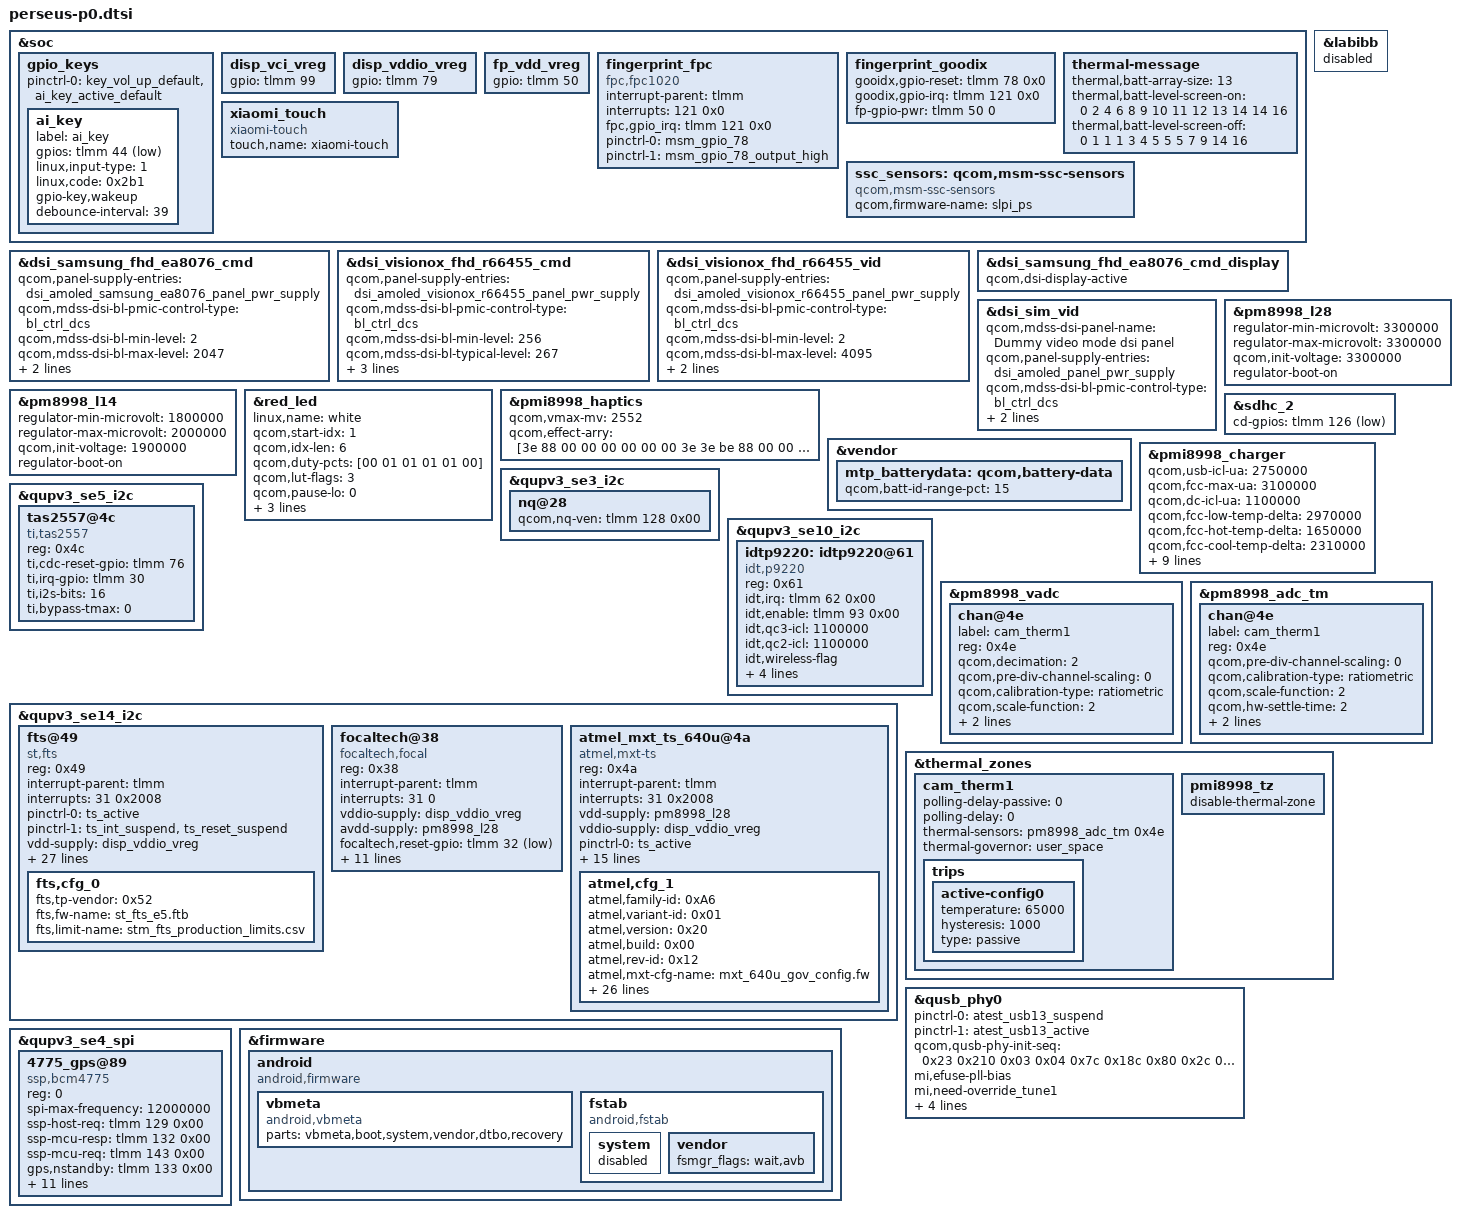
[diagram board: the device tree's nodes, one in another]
/* Copyright (c) 2016-2017, The Linux Foundation. All rights reserved.
 * Copyright (C) 2019 XiaoMi, Inc.
 *
 * This program is free software; you can redistribute it and/or modify
 * it under the terms of the GNU General Public License version 2 and
 * only version 2 as published by the Free Software Foundation.
 *
 * This program is distributed in the hope that it will be useful,
 * but WITHOUT ANY WARRANTY; without even the implied warranty of
 * MERCHANTABILITY or FITNESS FOR A PARTICULAR PURPOSE.  See the
 * GNU General Public License for more details.
 */

#include "../xiaomi-sdm845-common.dtsi"
#include "perseus-p0-camera-sensor-mtp.dtsi"

&soc {
	gpio_keys {
		pinctrl-0 = <&key_vol_up_default &ai_key_active_default>;
		ai_key {
			label = "ai_key";
			gpios = <&tlmm 44 GPIO_ACTIVE_LOW>;
			linux,input-type = <1>;
			linux,code = <0x2b1>;
			gpio-key,wakeup;
			debounce-interval = <39>;
		};
	};

	disp_vci_vreg {
		gpio = <&tlmm 99 0>;
	};

	disp_vddio_vreg {
		gpio = <&tlmm 79 0>;
	 };

	fp_vdd_vreg {
		gpio = <&tlmm 50 0>;
	};

	fingerprint_fpc {
		status = "ok";
		compatible = "fpc,fpc1020";
		interrupt-parent = <&tlmm>;
		interrupts = <121 0x0>;
		fpc,gpio_irq    = <&tlmm 121 0x0>;
		/* fpc,enable-on-boot; */
		/* fpc,enable-wakeup;  */

		pinctrl-names = "fpc1020_reset_reset",
			"fpc1020_reset_active";

		pinctrl-0 = <&msm_gpio_78>;
		pinctrl-1 = <&msm_gpio_78_output_high>;
	};

	fingerprint_goodix {
		gooidx,gpio-reset = <&tlmm 78 0x0>;
		goodix,gpio-irq = <&tlmm 121 0x0>;
		fp-gpio-pwr = <&tlmm 50 0>;
	};

	thermal-message {
		thermal,batt-array-size = "13";
		thermal,batt-level-screen-on = "0 2 4 6 8 9 10 11 12 13 14 14 16";
		thermal,batt-level-screen-off = "0 1 1 1 3 4 5 5 5 7 9 14 16";
	};

	xiaomi_touch {
		compatible = "xiaomi-touch";
		status = "ok";
		touch,name = "xiaomi-touch";
	};

};

&labibb {
	status = "disabled";
};

&dsi_samsung_fhd_ea8076_cmd {
	qcom,panel-supply-entries = <&dsi_amoled_samsung_ea8076_panel_pwr_supply>;
	qcom,mdss-dsi-bl-pmic-control-type = "bl_ctrl_dcs";
	qcom,mdss-dsi-bl-min-level = <2>;
	qcom,mdss-dsi-bl-max-level = <2047>;
	qcom,platform-reset-gpio = <&tlmm 6 0>;
	qcom,platform-te-gpio = <&tlmm 10 0>;
};

&dsi_visionox_fhd_r66455_cmd {
	qcom,panel-supply-entries = <&dsi_amoled_visionox_r66455_panel_pwr_supply>;
	qcom,mdss-dsi-bl-pmic-control-type = "bl_ctrl_dcs";
	qcom,mdss-dsi-bl-min-level = <256>;
	qcom,mdss-dsi-bl-typical-level = <267>;
	qcom,mdss-dsi-bl-max-level = <4095>;
	qcom,platform-reset-gpio = <&tlmm 6 0>;
	qcom,platform-te-gpio = <&tlmm 10 0>;
};

&dsi_visionox_fhd_r66455_vid {
	qcom,panel-supply-entries = <&dsi_amoled_visionox_r66455_panel_pwr_supply>;
	qcom,mdss-dsi-bl-pmic-control-type = "bl_ctrl_dcs";
	qcom,mdss-dsi-bl-min-level = <2>;
	qcom,mdss-dsi-bl-max-level = <4095>;
	qcom,platform-reset-gpio = <&tlmm 6 0>;
	qcom,platform-te-gpio = <&tlmm 10 0>;
};

&dsi_samsung_fhd_ea8076_cmd_display {
	qcom,dsi-display-active;
};

&dsi_sim_vid {
	qcom,mdss-dsi-panel-name = "Dummy video mode dsi panel";
	qcom,panel-supply-entries = <&dsi_amoled_panel_pwr_supply>;
	qcom,mdss-dsi-bl-pmic-control-type = "bl_ctrl_dcs";
	qcom,platform-reset-gpio = <&tlmm 6 0>;
	qcom,mdss-dsi-te-pin-select = <0>;
};

&pm8998_l28{
	regulator-min-microvolt = <3300000>;
	regulator-max-microvolt = <3300000>;
	qcom,init-voltage = <3300000>;
	regulator-boot-on;
};

&pm8998_l14 {
	regulator-min-microvolt = <1800000>;
	regulator-max-microvolt = <2000000>;
	qcom,init-voltage = <1900000>;
	regulator-boot-on;
};

&red_led {
	linux,name = "white";
	qcom,start-idx = <1>;
	qcom,idx-len = <6>;
	qcom,duty-pcts = [00 01 01 01 01 00];
	qcom,lut-flags = <3>;
	qcom,pause-lo = <0>;
	qcom,pause-hi = <0>;
	qcom,ramp-step-ms = <400>;
	qcom,use-blink;
	status = "okay";
};

&pmi8998_haptics {
	qcom,vmax-mv = <2552>;
	qcom,effect-arry = [3e 88 00 00 00 00 00 00
	3e 3e be 88 00 00 00 00
	3e 3e 3e be a0 00 00 00];
};

&sdhc_2 {
	cd-gpios = <&tlmm 126 GPIO_ACTIVE_LOW>;
};

&vendor{
	mtp_batterydata: qcom,battery-data {
		qcom,batt-id-range-pct = <15>;
		#include "../battery/batterydata-e5-sun-3200mAh.dtsi"
		#include "../battery/batterydata-e5-cos-3200mAh.dtsi"
		#include "../battery/batterydata-itech-3020mAh.dtsi"
	};
};

&pmi8998_charger {
	qcom,usb-icl-ua = <2750000>;
	qcom,fcc-max-ua = <3100000>;
	qcom,dc-icl-ua = <1100000>;
	qcom,fcc-low-temp-delta = <2970000>;
	qcom,fcc-hot-temp-delta = <1650000>;
	qcom,fcc-cool-temp-delta = <2310000>;
	qcom,use-ext-boost;
	qcom,wireless-support;
	qcom,thermal-mitigation-dc
				= <1100000 700000 525000 450000 325000>;
	qcom,thermal-mitigation-qc3
				= <2800000 2725000 2575000 2425000 2275000 2125000 2000000
				   1800000 1650000 1500000 1360000 1200000 1060000 900000
				   752500 525000>;

	io-channels = <&pmi8998_rradc 8>,
		<&pmi8998_rradc 10>,
		<&pmi8998_rradc 3>,
		<&pmi8998_rradc 4>,
		<&pmi8998_rradc 5>;
	io-channel-names = "charger_temp",
		"charger_temp_max",
		"usbin_i",
		"usbin_v",
		"dcin_i";
};

&qupv3_se3_i2c {
	status = "ok";
	nq@28 {
		qcom,nq-ven = <&tlmm 128 0x00>;
	};
};

&qupv3_se5_i2c {
	status = "ok";
	/*smart PA*/
	tas2557@4c{
		compatible = "ti,tas2557";
		reg = <0x4c>;
		ti,cdc-reset-gpio = <&tlmm 76 0>;
		ti,irq-gpio = <&tlmm 30 0>;
		ti,i2s-bits = <16>;
		ti,bypass-tmax = <0>;
	};
};

&qupv3_se10_i2c {
	status = "ok";
	idtp9220: idtp9220@61 {
		compatible = "idt,p9220";
		reg = <0x61>;
		idt,irq = <&tlmm 62 0x00>;
		idt,enable = <&tlmm 93 0x00>;
		idt,qc3-icl = <1100000>;
		idt,qc2-icl = <1100000>;
		idt,wireless-flag;
		interrupt-parent = <&tlmm>;
		interrupts = <62 0>;
		interrupt-names = "idt_irq";
		pinctrl-names = "idt_active", "idt_suspend";
		pinctrl-0 = <&idt_int_active &idt_enable_active>;
		pinctrl-1 = <&idt_int_suspend &idt_enable_suspend>;
	};
};

&qupv3_se14_i2c {
	status = "ok";
	fts@49 {
		compatible = "st,fts";
		reg = <0x49>;
		interrupt-parent = <&tlmm>;
		interrupts = <31 0x2008>;
		pinctrl-names = "pmx_ts_active", "pmx_ts_suspend";
		pinctrl-0 = <&ts_active>;
		pinctrl-1 = <&ts_int_suspend &ts_reset_suspend>;
		vdd-supply = <&disp_vddio_vreg>;
		avdd-supply = <&pm8998_l28>;
		fts,pwr-reg-name = "avdd";
		fts,bus-reg-name = "vdd";
		fts,irq-gpio = <&tlmm 31 0x2008>;
		fts,irq-gpio-name = "fts_irq";
		fts,reset-gpio-enable;
		fts,reset-gpio = <&tlmm 32 0x00>;
		fts,x-max = <1079>;
		fts,y-max = <2339>;
		fts,reset-gpio-name = "fts_rst";
		fts,irq-flags = <0x2008>; /* IRQF_ONESHOT | IRQF_TRIGGER_LOW */
		fts,key-num = <2>;
		fts,key-codes = <158 139>;
		fts,config-array-size = <1>;
		fts,check-display-name;
		fts,default-fw-name = "st_fts_e5.ftb";
		fts,touch-up-threshold-min = <20>;
		fts,touch-up-threshold-max = <170>;
		fts,touch-up-threshold-def = <20>;
		fts,touch-tolerance-min = <5>;
		fts,touch-tolerance-max = <35>;
		fts,touch-tolerance-def = <5>;
		fts,edgefilter-leftrigt-def = <40>;
		fts,edgefilter-topbottom-def = <40>;
		fts,edgefilter-area-step1 = <100>;
		fts,edgefilter-area-step2 = <150>;
		fts,edgefilter-area-step3 = <250>;
		fts,cfg_0 {
			fts,tp-vendor = <0x52>;
			fts,fw-name = "st_fts_e5.ftb";
			fts,limit-name = "stm_fts_production_limits.csv";
		};
	};
	focaltech@38 {
		compatible = "focaltech,focal";
		reg = <0x38>;
		interrupt-parent = <&tlmm>;
		interrupts = <31 0>;
		vddio-supply = <&disp_vddio_vreg>;
		avdd-supply = <&pm8998_l28>;

		focaltech,reset-gpio = <&tlmm 32 0x01>;
		focaltech,irq-gpio = <&tlmm 31 0x02>;
		focaltech,max-touch-number = <10>;
		focaltech,display-coords = <0 0 1080 2340>;
		focaltech,project-name = "e5";
		focaltech,lockdown-info-addr = <0x1FFD0>;
		focaltech,reset-when-resume;
		focaltech,open-min = <3000>;
		focaltech,timeout-read-reg = <2000>;
		focaltech,check-display-name;
		pinctrl-names = "pmx_ts_active", "pmx_ts_suspend";
		pinctrl-0 = <&ts_active>;
		pinctrl-1 = <&ts_int_suspend &ts_reset_suspend>;
		/* focaltech,have-key; */
	};
	atmel_mxt_ts_640u@4a {
		compatible = "atmel,mxt-ts";
		reg = <0x4a>;
		interrupt-parent = <&tlmm>;
		interrupts = <31 0x2008>;
		vdd-supply = <&pm8998_l28>;
		vddio-supply = <&disp_vddio_vreg>;
		/* pins used by touchscreen */
		pinctrl-names = "pmx_ts_active","pmx_ts_suspend";
		pinctrl-0 = <&ts_active>;
		pinctrl-1 = <&ts_int_suspend &ts_reset_suspend>;
		atmel,reset-gpio = <&tlmm 32 0x00>;
		atmel,reset-low-prepower;
		atmel,irq-gpio = <&tlmm 31 0x2008>;
		atmel,mxt-fw-name = "mXT640U2000.fw";
		atmel,config-array-size = <1>;
		atmel,default-config = <0>;
		atmel,default-panel-id = <0x51>;
		atmel,irqflags = <0x2008>;
		atmel,gpio-mask = <0xC>;
		atmel,esd-reset;
		atmel,no-keys;
		atmel,use-ta-gpio;
		atmel,raw-min = <3000>;
		atmel,raw-max = <7000>;
		atmel,cfg_1 {
			atmel,family-id = <0xA6>;
			atmel,variant-id = <0x01>;
			atmel,version = <0x20>;
			atmel,build = <0x00>;
			atmel,rev-id = <0x12>;
			atmel,mxt-cfg-name = "mxt_640u_gov_config.fw";
			atmel,vendor-id = <0x0C>;
			atmel,panel-id = <0x51>; /* gov id = 0x51 */
			atmel,key-codes = <158 139 102>;
			atmel,selfintthr-stylus = <0>;
			atmel,t71-tchthr-pos = <22>;
			atmel,self-chgtime-min = <0>;
			atmel,self-chgtime-max = <0>;
			atmel,mult-intthr-sensitive = <0x08>;
			atmel,mult-intthr-not-sensitive = <17>;
			atmel,atchthr-sensitive = <6>;
			atmel,mult-tchthr-sensitive = <0x14>;
			atmel,mult-tchthr-not-sensitive = <0>;
			atmel,wake-up-self-adcx = <16>;
			atmel,atchratio = <0>;
			atmel,xycfg = <0x08>;
			atmel,xsize = <0x1e>;
			atmel,xrange-lsb = <0x37>;
			atmel,xrange-msb = <0x04>;
			atmel,tchhyst = <0x0a>;
			atmel,intthrhyst = <0x03>;
			atmel,xtchthr = <0x23>;
			atmel,xtchhyst = <0x0f>;
			atmel,intthrx = <0x08>;
			atmel,ytchthr = <0x23>;
			atmel,ytchhyst = <0x0f>;
			atmel,intthry = <0x08>;
		};
	};
};

&pm8998_vadc {
	chan@4e {
		label = "cam_therm1";
		reg = <0x4e>;
		qcom,decimation = <2>;
		qcom,pre-div-channel-scaling = <0>;
		qcom,calibration-type = "ratiometric";
		qcom,scale-function = <2>;
		qcom,hw-settle-time = <2>;
		qcom,fast-avg-setup = <0>;
	};
};

&pm8998_adc_tm {
	chan@4e {
		label = "cam_therm1";
		reg = <0x4e>;
		qcom,pre-div-channel-scaling = <0>;
		qcom,calibration-type = "ratiometric";
		qcom,scale-function = <2>;
		qcom,hw-settle-time = <2>;
		qcom,btm-channel-number = <0x70>;
		qcom,thermal-node;
	};
};

&thermal_zones {
	cam_therm1 {
		polling-delay-passive = <0>;
		polling-delay = <0>;
		thermal-sensors = <&pm8998_adc_tm 0x4e>;
		thermal-governor = "user_space";

		trips {
			active-config0 {
					temperature = <65000>;
					hysteresis = <1000>;
					type = "passive";
			};
		};
	};

	pmi8998_tz {
		disable-thermal-zone;
	};
};

&qusb_phy0 {
	pinctrl-names = "atest_usb13_suspend","atest_usb13_active";
	pinctrl-0 = <&atest_usb13_suspend>;
	pinctrl-1 = <&atest_usb13_active>;

	qcom,qusb-phy-init-seq =
		/* <value reg_offset> */
		   <0x23 0x210 /* PWR_CTRL1 */
		    0x03 0x04  /* PLL_ANALOG_CONTROLS_TWO */
		    0x7c 0x18c /* PLL_CLOCK_INVERTERS */
		    0x80 0x2c  /* PLL_CMODE */
		    0x0a 0x184 /* PLL_LOCK_DELAY */
		    0x19 0xb4  /* PLL_DIGITAL_TIMERS_TWO */
		    0x40 0x194 /* PLL_BIAS_CONTROL_1 */
		    0x17 0x198 /* PLL_BIAS_CONTROL_2 */
		    0x21 0x214 /* PWR_CTRL2 */
		    0x08 0x220 /* IMP_CTRL1 */
		    0x58 0x224 /* IMP_CTRL2 */
		    0x07 0x240 /* TUNE1 */
		    0x2a 0x244 /* TUNE2 */
		    0xca 0x248 /* TUNE3 */
		    0x04 0x24c /* TUNE4 */
		    0x03 0x250 /* TUNE5 */
		    0x00 0x23c /* CHG_CTRL2 */
		    0x22 0x210>; /* PWR_CTRL1 */
	mi,efuse-pll-bias;
	mi,need-override_tune1;
	mi,override_tune1 = <1 0x17 2 0x17 3 0x17 4 0x17 5 0x47 6 0x47 7 0x47>;
	mi,efuse-pll-bias-seq = <1 0x21 2 0x19 3 0x17 4 0x15 5 0x19 6 0x19 7 0x15>;
};

&qupv3_se4_spi {
	status = "ok";
	4775_gps@89 {
		compatible = "ssp,bcm4775";
		reg = <0>;
		spi-max-frequency = <12000000>;
		ssp-host-req = <&tlmm 129 0x00>;
		ssp-mcu-resp = <&tlmm 132 0x00>;
		ssp-mcu-req = <&tlmm 143 0x00>;
		gps,nstandby = <&tlmm 133 0x00>;
		interrupt-parent = <&tlmm>;
		interrupts = <129 0>;
		spi-cpha;
		spi-cpol;
		interrupt-names = "gps_irq";
		gps,power_enable = <&pm8998_gpios 19 GPIO_ACTIVE_HIGH>;
		pinctrl-names = "gps_active", "gps_suspend";
		pinctrl-0 = <&gps_int_active
			&gps_enable_active
			&gps_clk_default
			&gps_power_default
			&gps_resp_active>;
		pinctrl-1 = <&gps_int_suspend &gps_enable_suspend &gps_resp_suspend>;
	};
};

&soc {
	ssc_sensors: qcom,msm-ssc-sensors {
		compatible = "qcom,msm-ssc-sensors";
		status = "ok";
		qcom,firmware-name = "slpi_ps";
	};
};

&firmware {
	android {
		compatible = "android,firmware";
		vbmeta {
			compatible = "android,vbmeta";
			parts = "vbmeta,boot,system,vendor,dtbo,recovery";
		};

		fstab {
			compatible = "android,fstab";
			system {
				status = "disabled";
			};
			vendor {
				fsmgr_flags = "wait,avb";
			};
		};
	};
};
